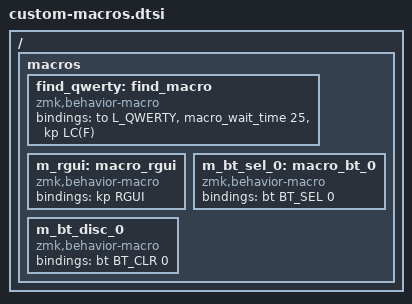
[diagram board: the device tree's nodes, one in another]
/ { 
    macros {

        // Macro to switch to qwerty layer and find (ctrl+f)
        find_qwerty: find_macro {
            compatible = "zmk,behavior-macro";
            #binding-cells = <0>;
            bindings = <&to L_QWERTY>, <&macro_wait_time 25>, <&kp LC(F)>;
        };

        // RGUI macro for workaround
        m_rgui: macro_rgui {
            compatible = "zmk,behavior-macro";
            #binding-cells = <0>;
            bindings = <&kp RGUI>;
        };

        // // Bluetooth profile select macros
        m_bt_sel_0: macro_bt_0 {
            compatible = "zmk,behavior-macro";
            #binding-cells = <0>;
            bindings = <&bt BT_SEL 0>;
        };
        // m_bt_sel_1: macro_bt_1 {
        //     compatible = "zmk,behavior-macro";
        //     #binding-cells = <0>;
        //     bindings = <&bt BT_SEL 1>;
        // };
        // m_bt_sel_2: macro_bt_2 {
        //     compatible = "zmk,behavior-macro";
        //     #binding-cells = <0>;
        //     bindings = <&bt BT_SEL 2>;
        // };
        // m_bt_sel_3: macro_bt_3 {
        //     compatible = "zmk,behavior-macro";
        //     #binding-cells = <0>;
        //     bindings = <&bt BT_SEL 3>;
        // };
        // m_bt_sel_4: macro_bt_4 {
        //     compatible = "zmk,behavior-macro";
        //     #binding-cells = <0>;
        //     bindings = <&bt BT_SEL 4>;
        // };

        // // Bluetooth disconnect profile macros
        m_bt_disc_0: m_bt_disc_0 {
            compatible = "zmk,behavior-macro";
            #binding-cells = <0>;
            bindings = <&bt BT_CLR 0>;
        };
        // m_bt_disc_1: macro_bt_disc_1 {
        //     compatible = "zmk,behavior-macro";
        //     #binding-cells = <0>;
        //     bindings = <&bt BT_CLR 1>;
        // };
        // m_bt_disc_2: macro_bt_disc_2 {
        //     compatible = "zmk,behavior-macro";
        //     #binding-cells = <0>;
        //     bindings = <&bt BT_CLR 2>;
        // };
        // m_bt_disc_3: macro_bt_disc_3 {
        //     compatible = "zmk,behavior-macro";
        //     #binding-cells = <0>;
        //     bindings = <&bt BT_CLR 3>;
        // };
        // m_bt_disc_4: macro_bt_disc_4 {
        //     compatible = "zmk,behavior-macro";
        //     #binding-cells = <0>;
        //     bindings = <&bt BT_CLR 4>;
        // };

    };
};
